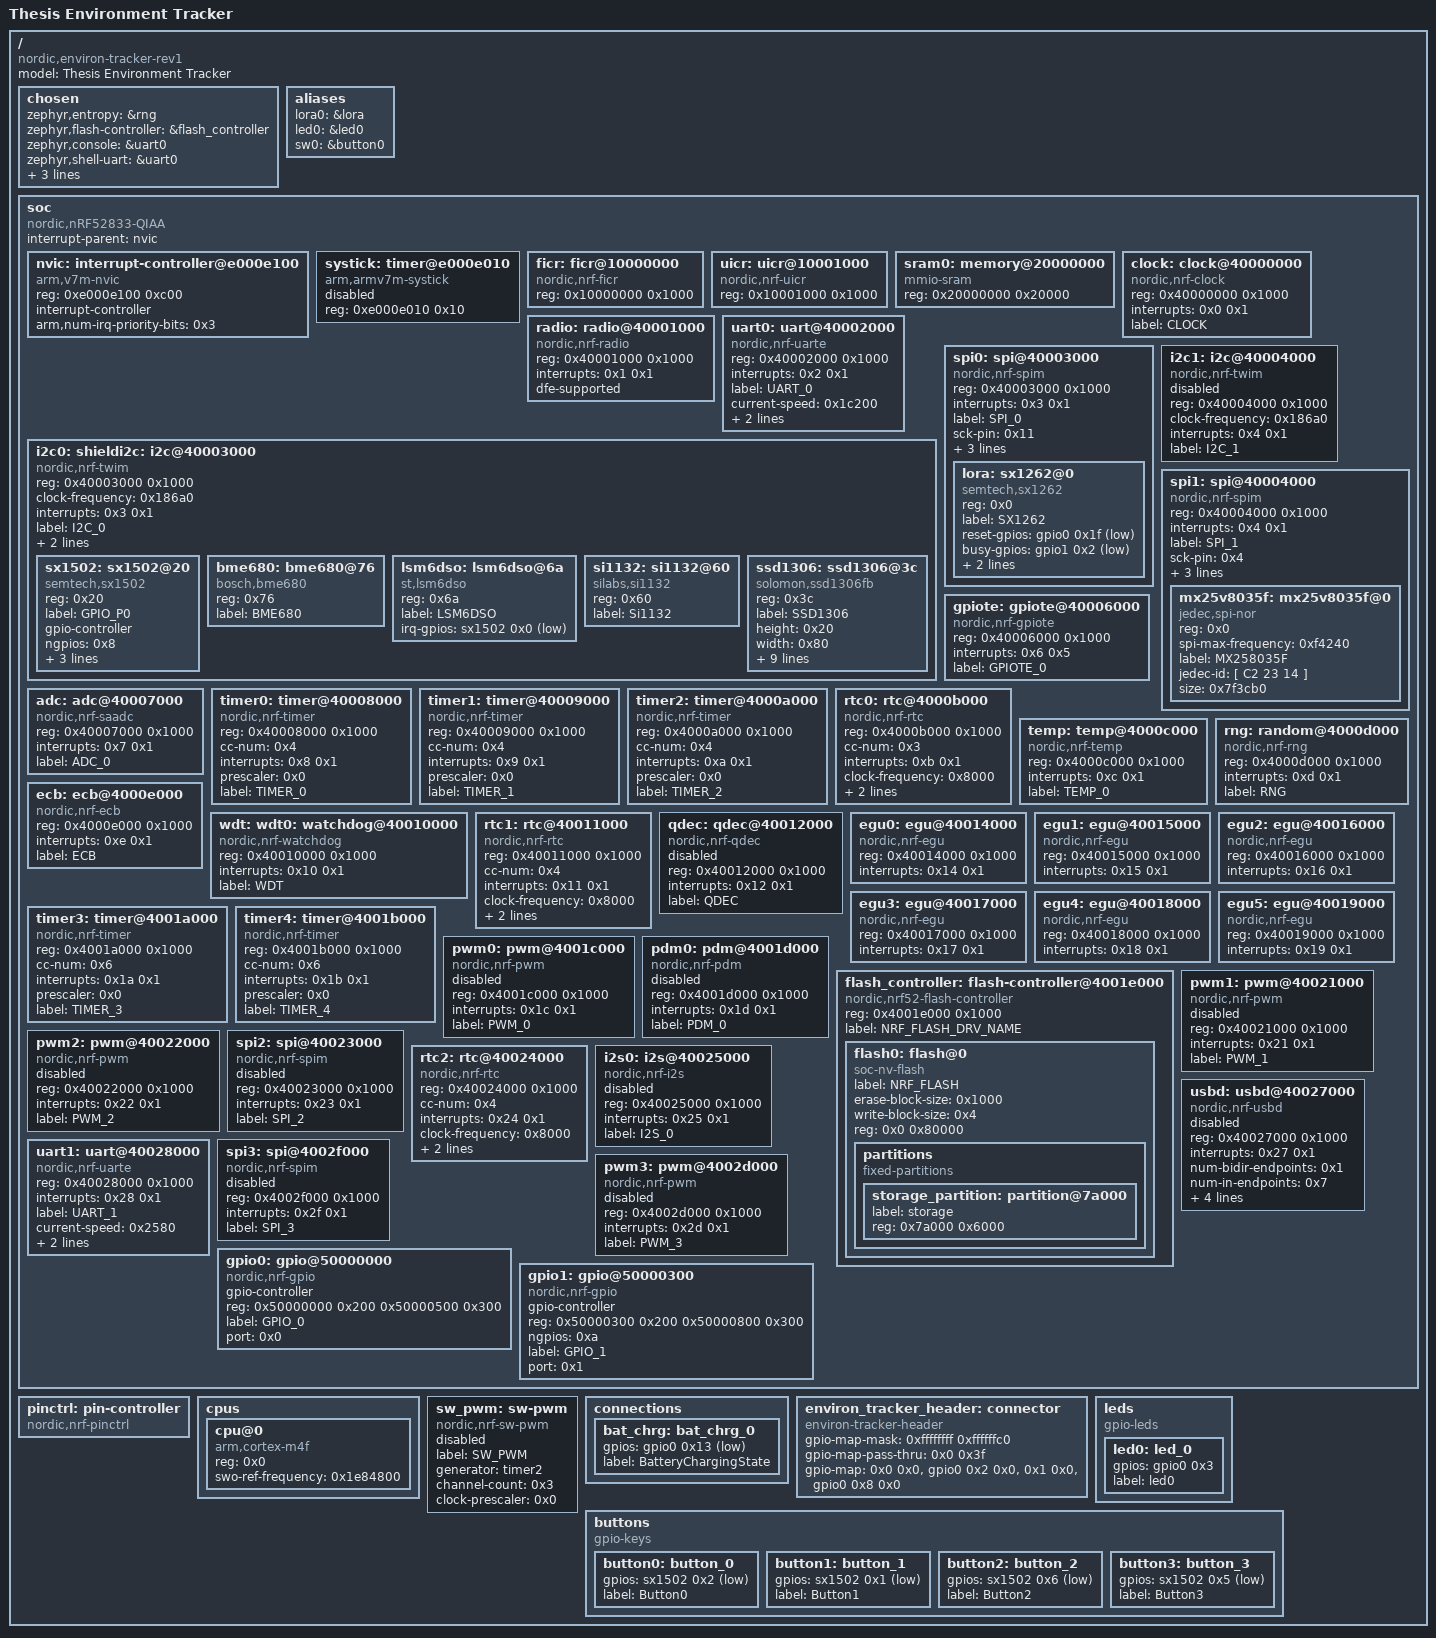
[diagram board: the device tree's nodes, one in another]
/dts-v1/;

/ {
	#address-cells = < 0x1 >;
	#size-cells = < 0x1 >;
	model = "Thesis Environment Tracker";
	compatible = "nordic,environ-tracker-rev1";
	chosen {
		zephyr,entropy = &rng;
		zephyr,flash-controller = &flash_controller;
		zephyr,console = &uart0;
		zephyr,shell-uart = &uart0;
		zephyr,sram = &sram0;
		zephyr,flash = &flash0;
		zephyr,code-partition = &flash0;
	};
	aliases {
		lora0 = &lora;
		led0 = &led0;
		sw0 = &button0;
	};
	soc {
		#address-cells = < 0x1 >;
		#size-cells = < 0x1 >;
		compatible = "nordic,nRF52833-QIAA", "nordic,nRF52833", "nordic,nRF52", "simple-bus";
		interrupt-parent = < &nvic >;
		ranges;
		nvic: interrupt-controller@e000e100 {
			#address-cells = < 0x1 >;
			compatible = "arm,v7m-nvic";
			reg = < 0xe000e100 0xc00 >;
			interrupt-controller;
			#interrupt-cells = < 0x2 >;
			arm,num-irq-priority-bits = < 0x3 >;
			phandle = < 0x1 >;
		};
		systick: timer@e000e010 {
			compatible = "arm,armv7m-systick";
			reg = < 0xe000e010 0x10 >;
			status = "disabled";
		};
		ficr: ficr@10000000 {
			compatible = "nordic,nrf-ficr";
			reg = < 0x10000000 0x1000 >;
			status = "okay";
		};
		uicr: uicr@10001000 {
			compatible = "nordic,nrf-uicr";
			reg = < 0x10001000 0x1000 >;
			status = "okay";
		};
		sram0: memory@20000000 {
			compatible = "mmio-sram";
			reg = < 0x20000000 0x20000 >;
		};
		clock: clock@40000000 {
			compatible = "nordic,nrf-clock";
			reg = < 0x40000000 0x1000 >;
			interrupts = < 0x0 0x1 >;
			status = "okay";
			label = "CLOCK";
		};
		radio: radio@40001000 {
			compatible = "nordic,nrf-radio";
			reg = < 0x40001000 0x1000 >;
			interrupts = < 0x1 0x1 >;
			status = "okay";
			dfe-supported;
		};
		uart0: uart@40002000 {
			compatible = "nordic,nrf-uarte";
			reg = < 0x40002000 0x1000 >;
			interrupts = < 0x2 0x1 >;
			status = "okay";
			label = "UART_0";
			current-speed = < 0x1c200 >;
			tx-pin = < 0xf >;
			rx-pin = < 0xd >;
		};
		i2c0: shieldi2c: i2c@40003000 {
			compatible = "nordic,nrf-twim";
			#address-cells = < 0x1 >;
			#size-cells = < 0x0 >;
			reg = < 0x40003000 0x1000 >;
			clock-frequency = < 0x186a0 >;
			interrupts = < 0x3 0x1 >;
			status = "okay";
			label = "I2C_0";
			sda-pin = < 0xc >;
			scl-pin = < 0x29 >;
			sx1502: sx1502@20 {
				compatible = "semtech,sx1502";
				reg = < 0x20 >;
				label = "GPIO_P0";
				gpio-controller;
				#gpio-cells = < 0x2 >;
				ngpios = < 0x8 >;
				nint-gpios = < &environ_tracker_header 0x1 0x1 >;
				init-out-high = < 0xff >;
				init-out-low = < 0x0 >;
				phandle = < 0x3 >;
			};
			bme680: bme680@76 {
				compatible = "bosch,bme680";
				reg = < 0x76 >;
				label = "BME680";
			};
			lsm6dso: lsm6dso@6a {
				compatible = "st,lsm6dso";
				reg = < 0x6a >;
				label = "LSM6DSO";
				irq-gpios = < &sx1502 0x0 0x1 >;
			};
			si1132: si1132@60 {
				compatible = "silabs,si1132";
				reg = < 0x60 >;
				label = "Si1132";
			};
			ssd1306: ssd1306@3c {
				compatible = "solomon,ssd1306fb";
				reg = < 0x3c >;
				label = "SSD1306";
				height = < 0x20 >;
				width = < 0x80 >;
				segment-offset = < 0x0 >;
				page-offset = < 0x0 >;
				display-offset = < 0x0 >;
				multiplex-ratio = < 0x1f >;
				prechargep = < 0xd1 >;
				segment-remap;
				com-invdir;
				com-sequential;
				reset-gpios = < &sx1502 0x7 0x1 >;
			};
		};
		spi0: spi@40003000 {
			compatible = "nordic,nrf-spim";
			#address-cells = < 0x1 >;
			#size-cells = < 0x0 >;
			reg = < 0x40003000 0x1000 >;
			interrupts = < 0x3 0x1 >;
			status = "okay";
			label = "SPI_0";
			sck-pin = < 0x11 >;
			mosi-pin = < 0x14 >;
			miso-pin = < 0x16 >;
			cs-gpios = < &gpio0 0x1d 0x1 >;
			lora: sx1262@0 {
				compatible = "semtech,sx1262";
				reg = < 0x0 >;
				label = "SX1262";
				reset-gpios = < &gpio0 0x1f 0x1 >;
				busy-gpios = < &gpio1 0x2 0x1 >;
				dio1-gpios = < &gpio1 0x4 0x0 >;
				spi-max-frequency = < 0xf4240 >;
			};
		};
		i2c1: i2c@40004000 {
			compatible = "nordic,nrf-twim";
			#address-cells = < 0x1 >;
			#size-cells = < 0x0 >;
			reg = < 0x40004000 0x1000 >;
			clock-frequency = < 0x186a0 >;
			interrupts = < 0x4 0x1 >;
			status = "disabled";
			label = "I2C_1";
		};
		spi1: spi@40004000 {
			compatible = "nordic,nrf-spim";
			#address-cells = < 0x1 >;
			#size-cells = < 0x0 >;
			reg = < 0x40004000 0x1000 >;
			interrupts = < 0x4 0x1 >;
			status = "okay";
			label = "SPI_1";
			sck-pin = < 0x4 >;
			mosi-pin = < 0x6 >;
			miso-pin = < 0x1a >;
			cs-gpios = < &gpio1 0x5 0x1 >;
			mx25v8035f: mx25v8035f@0 {
				compatible = "jedec,spi-nor";
				reg = < 0x0 >;
				spi-max-frequency = < 0xf4240 >;
				label = "MX258035F";
				jedec-id = [ C2 23 14 ];
				size = < 0x7f3cb0 >;
			};
		};
		gpiote: gpiote@40006000 {
			compatible = "nordic,nrf-gpiote";
			reg = < 0x40006000 0x1000 >;
			interrupts = < 0x6 0x5 >;
			status = "okay";
			label = "GPIOTE_0";
		};
		adc: adc@40007000 {
			compatible = "nordic,nrf-saadc";
			reg = < 0x40007000 0x1000 >;
			interrupts = < 0x7 0x1 >;
			status = "okay";
			label = "ADC_0";
			#io-channel-cells = < 0x1 >;
		};
		timer0: timer@40008000 {
			compatible = "nordic,nrf-timer";
			status = "okay";
			reg = < 0x40008000 0x1000 >;
			cc-num = < 0x4 >;
			interrupts = < 0x8 0x1 >;
			prescaler = < 0x0 >;
			label = "TIMER_0";
		};
		timer1: timer@40009000 {
			compatible = "nordic,nrf-timer";
			status = "okay";
			reg = < 0x40009000 0x1000 >;
			cc-num = < 0x4 >;
			interrupts = < 0x9 0x1 >;
			prescaler = < 0x0 >;
			label = "TIMER_1";
		};
		timer2: timer@4000a000 {
			compatible = "nordic,nrf-timer";
			status = "okay";
			reg = < 0x4000a000 0x1000 >;
			cc-num = < 0x4 >;
			interrupts = < 0xa 0x1 >;
			prescaler = < 0x0 >;
			label = "TIMER_2";
			phandle = < 0x6 >;
		};
		rtc0: rtc@4000b000 {
			compatible = "nordic,nrf-rtc";
			reg = < 0x4000b000 0x1000 >;
			cc-num = < 0x3 >;
			interrupts = < 0xb 0x1 >;
			status = "okay";
			clock-frequency = < 0x8000 >;
			prescaler = < 0x1 >;
			label = "RTC_0";
		};
		temp: temp@4000c000 {
			compatible = "nordic,nrf-temp";
			reg = < 0x4000c000 0x1000 >;
			interrupts = < 0xc 0x1 >;
			status = "okay";
			label = "TEMP_0";
		};
		rng: random@4000d000 {
			compatible = "nordic,nrf-rng";
			reg = < 0x4000d000 0x1000 >;
			interrupts = < 0xd 0x1 >;
			status = "okay";
			label = "RNG";
		};
		ecb: ecb@4000e000 {
			compatible = "nordic,nrf-ecb";
			reg = < 0x4000e000 0x1000 >;
			interrupts = < 0xe 0x1 >;
			status = "okay";
			label = "ECB";
		};
		wdt: wdt0: watchdog@40010000 {
			compatible = "nordic,nrf-watchdog";
			reg = < 0x40010000 0x1000 >;
			interrupts = < 0x10 0x1 >;
			status = "okay";
			label = "WDT";
		};
		rtc1: rtc@40011000 {
			compatible = "nordic,nrf-rtc";
			reg = < 0x40011000 0x1000 >;
			cc-num = < 0x4 >;
			interrupts = < 0x11 0x1 >;
			status = "okay";
			clock-frequency = < 0x8000 >;
			prescaler = < 0x1 >;
			label = "RTC_1";
		};
		qdec: qdec@40012000 {
			compatible = "nordic,nrf-qdec";
			reg = < 0x40012000 0x1000 >;
			interrupts = < 0x12 0x1 >;
			status = "disabled";
			label = "QDEC";
		};
		egu0: egu@40014000 {
			compatible = "nordic,nrf-egu";
			reg = < 0x40014000 0x1000 >;
			interrupts = < 0x14 0x1 >;
			status = "okay";
		};
		egu1: egu@40015000 {
			compatible = "nordic,nrf-egu";
			reg = < 0x40015000 0x1000 >;
			interrupts = < 0x15 0x1 >;
			status = "okay";
		};
		egu2: egu@40016000 {
			compatible = "nordic,nrf-egu";
			reg = < 0x40016000 0x1000 >;
			interrupts = < 0x16 0x1 >;
			status = "okay";
		};
		egu3: egu@40017000 {
			compatible = "nordic,nrf-egu";
			reg = < 0x40017000 0x1000 >;
			interrupts = < 0x17 0x1 >;
			status = "okay";
		};
		egu4: egu@40018000 {
			compatible = "nordic,nrf-egu";
			reg = < 0x40018000 0x1000 >;
			interrupts = < 0x18 0x1 >;
			status = "okay";
		};
		egu5: egu@40019000 {
			compatible = "nordic,nrf-egu";
			reg = < 0x40019000 0x1000 >;
			interrupts = < 0x19 0x1 >;
			status = "okay";
		};
		timer3: timer@4001a000 {
			compatible = "nordic,nrf-timer";
			status = "okay";
			reg = < 0x4001a000 0x1000 >;
			cc-num = < 0x6 >;
			interrupts = < 0x1a 0x1 >;
			prescaler = < 0x0 >;
			label = "TIMER_3";
		};
		timer4: timer@4001b000 {
			compatible = "nordic,nrf-timer";
			status = "okay";
			reg = < 0x4001b000 0x1000 >;
			cc-num = < 0x6 >;
			interrupts = < 0x1b 0x1 >;
			prescaler = < 0x0 >;
			label = "TIMER_4";
		};
		pwm0: pwm@4001c000 {
			compatible = "nordic,nrf-pwm";
			reg = < 0x4001c000 0x1000 >;
			interrupts = < 0x1c 0x1 >;
			status = "disabled";
			label = "PWM_0";
			#pwm-cells = < 0x1 >;
		};
		pdm0: pdm@4001d000 {
			compatible = "nordic,nrf-pdm";
			reg = < 0x4001d000 0x1000 >;
			interrupts = < 0x1d 0x1 >;
			status = "disabled";
			label = "PDM_0";
		};
		flash_controller: flash-controller@4001e000 {
			compatible = "nordic,nrf52-flash-controller";
			reg = < 0x4001e000 0x1000 >;
			#address-cells = < 0x1 >;
			#size-cells = < 0x1 >;
			label = "NRF_FLASH_DRV_NAME";
			flash0: flash@0 {
				compatible = "soc-nv-flash";
				label = "NRF_FLASH";
				erase-block-size = < 0x1000 >;
				write-block-size = < 0x4 >;
				reg = < 0x0 0x80000 >;
				partitions {
					compatible = "fixed-partitions";
					#address-cells = < 0x1 >;
					#size-cells = < 0x1 >;
					storage_partition: partition@7a000 {
						label = "storage";
						reg = < 0x7a000 0x6000 >;
					};
				};
			};
		};
		pwm1: pwm@40021000 {
			compatible = "nordic,nrf-pwm";
			reg = < 0x40021000 0x1000 >;
			interrupts = < 0x21 0x1 >;
			status = "disabled";
			label = "PWM_1";
			#pwm-cells = < 0x1 >;
		};
		pwm2: pwm@40022000 {
			compatible = "nordic,nrf-pwm";
			reg = < 0x40022000 0x1000 >;
			interrupts = < 0x22 0x1 >;
			status = "disabled";
			label = "PWM_2";
			#pwm-cells = < 0x1 >;
		};
		spi2: spi@40023000 {
			compatible = "nordic,nrf-spim";
			#address-cells = < 0x1 >;
			#size-cells = < 0x0 >;
			reg = < 0x40023000 0x1000 >;
			interrupts = < 0x23 0x1 >;
			status = "disabled";
			label = "SPI_2";
		};
		rtc2: rtc@40024000 {
			compatible = "nordic,nrf-rtc";
			reg = < 0x40024000 0x1000 >;
			cc-num = < 0x4 >;
			interrupts = < 0x24 0x1 >;
			status = "okay";
			clock-frequency = < 0x8000 >;
			prescaler = < 0x1 >;
			label = "RTC_2";
		};
		i2s0: i2s@40025000 {
			compatible = "nordic,nrf-i2s";
			#address-cells = < 0x1 >;
			#size-cells = < 0x0 >;
			reg = < 0x40025000 0x1000 >;
			interrupts = < 0x25 0x1 >;
			status = "disabled";
			label = "I2S_0";
		};
		usbd: usbd@40027000 {
			compatible = "nordic,nrf-usbd";
			reg = < 0x40027000 0x1000 >;
			interrupts = < 0x27 0x1 >;
			num-bidir-endpoints = < 0x1 >;
			num-in-endpoints = < 0x7 >;
			num-out-endpoints = < 0x7 >;
			num-isoin-endpoints = < 0x1 >;
			num-isoout-endpoints = < 0x1 >;
			status = "disabled";
			label = "USBD";
		};
		uart1: uart@40028000 {
			compatible = "nordic,nrf-uarte";
			reg = < 0x40028000 0x1000 >;
			interrupts = < 0x28 0x1 >;
			status = "okay";
			label = "UART_1";
			current-speed = < 0x2580 >;
			tx-pin = < 0x18 >;
			rx-pin = < 0x20 >;
		};
		pwm3: pwm@4002d000 {
			compatible = "nordic,nrf-pwm";
			reg = < 0x4002d000 0x1000 >;
			interrupts = < 0x2d 0x1 >;
			status = "disabled";
			label = "PWM_3";
			#pwm-cells = < 0x1 >;
		};
		spi3: spi@4002f000 {
			compatible = "nordic,nrf-spim";
			#address-cells = < 0x1 >;
			#size-cells = < 0x0 >;
			reg = < 0x4002f000 0x1000 >;
			interrupts = < 0x2f 0x1 >;
			status = "disabled";
			label = "SPI_3";
		};
		gpio0: gpio@50000000 {
			compatible = "nordic,nrf-gpio";
			gpio-controller;
			reg = < 0x50000000 0x200 0x50000500 0x300 >;
			#gpio-cells = < 0x2 >;
			label = "GPIO_0";
			status = "okay";
			port = < 0x0 >;
			phandle = < 0x4 >;
		};
		gpio1: gpio@50000300 {
			compatible = "nordic,nrf-gpio";
			gpio-controller;
			reg = < 0x50000300 0x200 0x50000800 0x300 >;
			#gpio-cells = < 0x2 >;
			ngpios = < 0xa >;
			label = "GPIO_1";
			status = "okay";
			port = < 0x1 >;
			phandle = < 0x5 >;
		};
	};
	pinctrl: pin-controller {
		compatible = "nordic,nrf-pinctrl";
	};
	cpus {
		#address-cells = < 0x1 >;
		#size-cells = < 0x0 >;
		cpu@0 {
			device_type = "cpu";
			compatible = "arm,cortex-m4f";
			reg = < 0x0 >;
			swo-ref-frequency = < 0x1e84800 >;
		};
	};
	sw_pwm: sw-pwm {
		compatible = "nordic,nrf-sw-pwm";
		status = "disabled";
		label = "SW_PWM";
		generator = < &timer2 >;
		channel-count = < 0x3 >;
		clock-prescaler = < 0x0 >;
		#pwm-cells = < 0x1 >;
	};
	connections {
		bat_chrg: bat_chrg_0 {
			gpios = < &gpio0 0x13 0x1 >;
			label = "BatteryChargingState";
		};
	};
	environ_tracker_header: connector {
		compatible = "environ-tracker-header";
		#gpio-cells = < 0x2 >;
		gpio-map-mask = < 0xffffffff 0xffffffc0 >;
		gpio-map-pass-thru = < 0x0 0x3f >;
		gpio-map = < 0x0 0x0 &gpio0 0x2 0x0 >, < 0x1 0x0 &gpio0 0x8 0x0 >;
		phandle = < 0x2 >;
	};
	leds {
		compatible = "gpio-leds";
		led0: led_0 {
			gpios = < &gpio0 0x3 0x0 >;
			label = "led0";
		};
	};
	buttons {
		compatible = "gpio-keys";
		button0: button_0 {
			gpios = < &sx1502 0x2 0x1 >;
			label = "Button0";
		};
		button1: button_1 {
			gpios = < &sx1502 0x1 0x1 >;
			label = "Button1";
		};
		button2: button_2 {
			gpios = < &sx1502 0x6 0x1 >;
			label = "Button2";
		};
		button3: button_3 {
			gpios = < &sx1502 0x5 0x1 >;
			label = "Button3";
		};
	};
};
